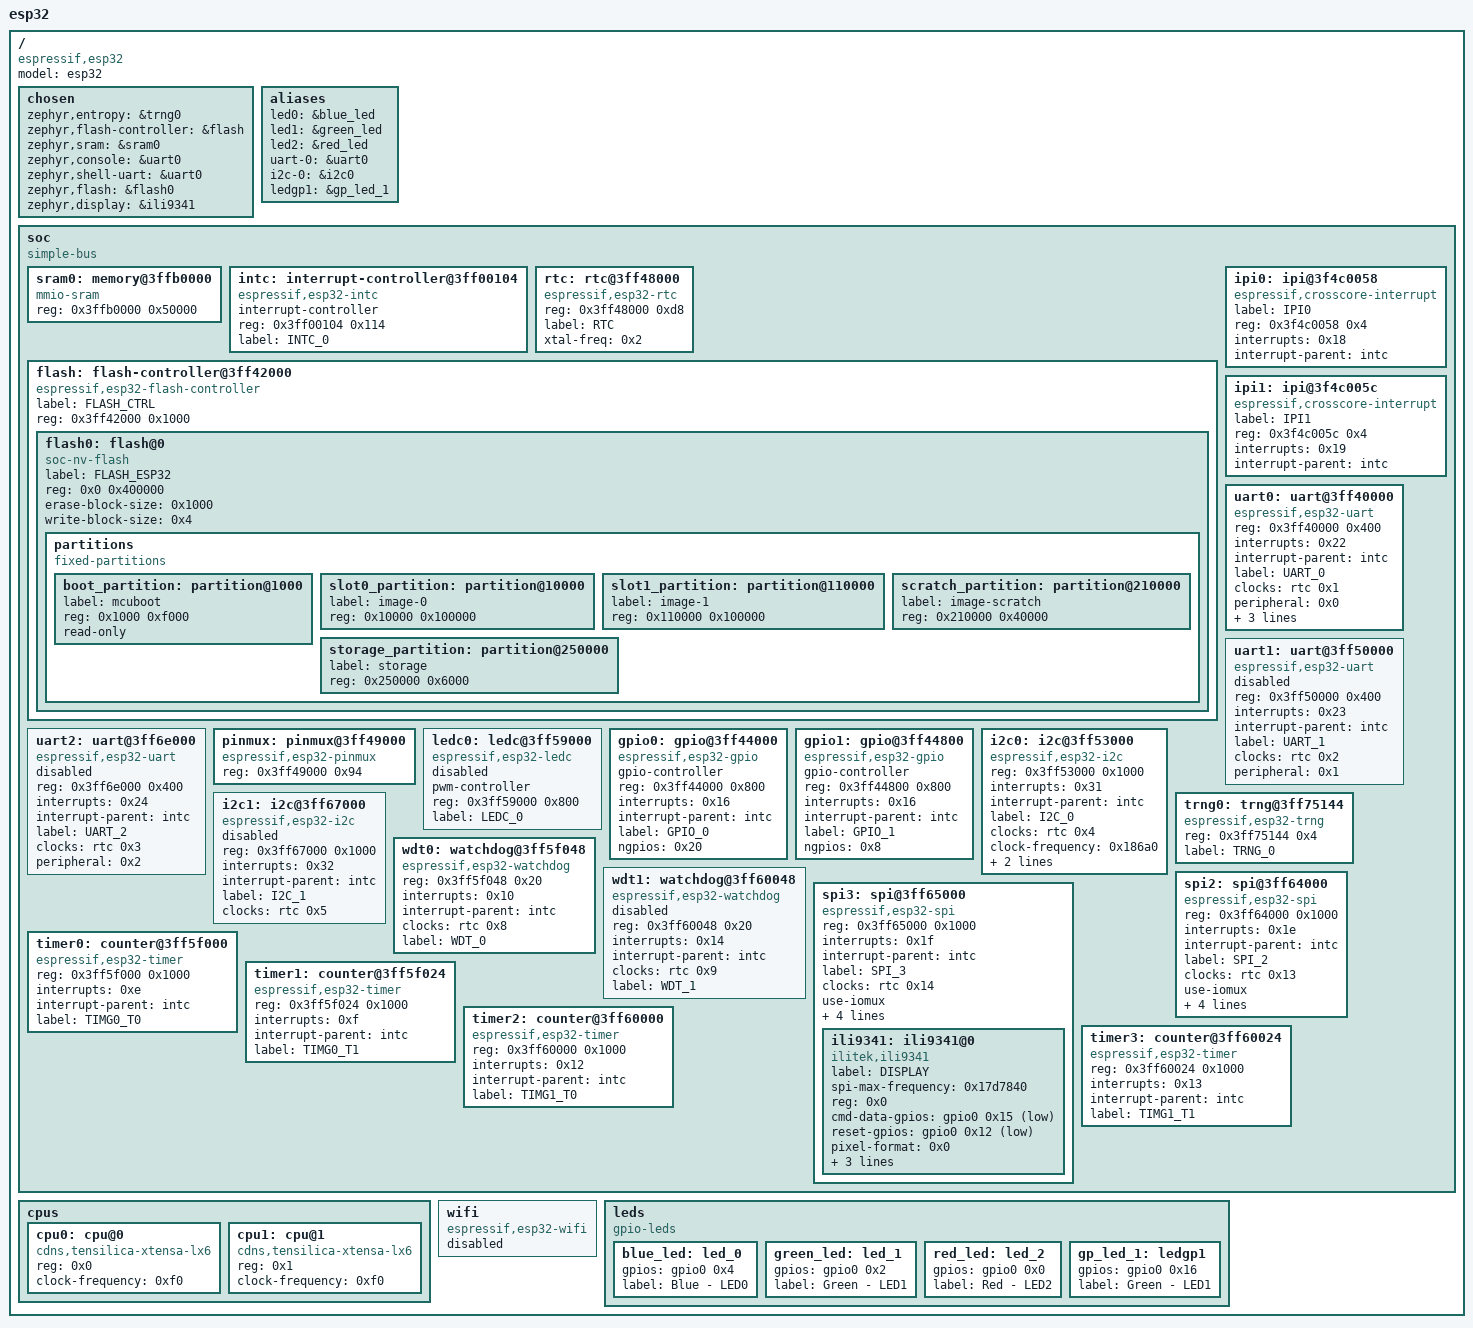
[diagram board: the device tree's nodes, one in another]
/dts-v1/;

/ {
	#address-cells = < 0x1 >;
	#size-cells = < 0x1 >;
	model = "esp32";
	compatible = "espressif,esp32";
	chosen {
		zephyr,entropy = &trng0;
		zephyr,flash-controller = &flash;
		zephyr,sram = &sram0;
		zephyr,console = &uart0;
		zephyr,shell-uart = &uart0;
		zephyr,flash = &flash0;
		zephyr,display = &ili9341;
	};
	aliases {
		led0 = &blue_led;
		led1 = &green_led;
		led2 = &red_led;
		uart-0 = &uart0;
		i2c-0 = &i2c0;
		ledgp1 = &gp_led_1;
	};
	soc {
		#address-cells = < 0x1 >;
		#size-cells = < 0x1 >;
		compatible = "simple-bus";
		ranges;
		sram0: memory@3ffb0000 {
			compatible = "mmio-sram";
			reg = < 0x3ffb0000 0x50000 >;
		};
		intc: interrupt-controller@3ff00104 {
			#interrupt-cells = < 0x1 >;
			compatible = "espressif,esp32-intc";
			interrupt-controller;
			reg = < 0x3ff00104 0x114 >;
			label = "INTC_0";
			status = "okay";
			phandle = < 0x1 >;
		};
		rtc: rtc@3ff48000 {
			compatible = "espressif,esp32-rtc";
			reg = < 0x3ff48000 0xd8 >;
			label = "RTC";
			xtal-freq = < 0x2 >;
			#clock-cells = < 0x1 >;
			status = "ok";
			phandle = < 0x2 >;
		};
		flash: flash-controller@3ff42000 {
			compatible = "espressif,esp32-flash-controller";
			label = "FLASH_CTRL";
			reg = < 0x3ff42000 0x1000 >;
			#address-cells = < 0x1 >;
			#size-cells = < 0x1 >;
			flash0: flash@0 {
				compatible = "soc-nv-flash";
				label = "FLASH_ESP32";
				reg = < 0x0 0x400000 >;
				erase-block-size = < 0x1000 >;
				write-block-size = < 0x4 >;
				status = "okay";
				partitions {
					compatible = "fixed-partitions";
					#address-cells = < 0x1 >;
					#size-cells = < 0x1 >;
					boot_partition: partition@1000 {
						label = "mcuboot";
						reg = < 0x1000 0xf000 >;
						read-only;
					};
					slot0_partition: partition@10000 {
						label = "image-0";
						reg = < 0x10000 0x100000 >;
					};
					slot1_partition: partition@110000 {
						label = "image-1";
						reg = < 0x110000 0x100000 >;
					};
					scratch_partition: partition@210000 {
						label = "image-scratch";
						reg = < 0x210000 0x40000 >;
					};
					storage_partition: partition@250000 {
						label = "storage";
						reg = < 0x250000 0x6000 >;
					};
				};
			};
		};
		ipi0: ipi@3f4c0058 {
			compatible = "espressif,crosscore-interrupt";
			label = "IPI0";
			reg = < 0x3f4c0058 0x4 >;
			interrupts = < 0x18 >;
			interrupt-parent = < &intc >;
		};
		ipi1: ipi@3f4c005c {
			compatible = "espressif,crosscore-interrupt";
			label = "IPI1";
			reg = < 0x3f4c005c 0x4 >;
			interrupts = < 0x19 >;
			interrupt-parent = < &intc >;
		};
		uart0: uart@3ff40000 {
			compatible = "espressif,esp32-uart";
			reg = < 0x3ff40000 0x400 >;
			interrupts = < 0x22 >;
			interrupt-parent = < &intc >;
			label = "UART_0";
			clocks = < &rtc 0x1 >;
			status = "okay";
			peripheral = < 0x0 >;
			current-speed = < 0x1c200 >;
			tx-pin = < 0x1 >;
			rx-pin = < 0x3 >;
		};
		uart1: uart@3ff50000 {
			compatible = "espressif,esp32-uart";
			reg = < 0x3ff50000 0x400 >;
			interrupts = < 0x23 >;
			interrupt-parent = < &intc >;
			label = "UART_1";
			clocks = < &rtc 0x2 >;
			status = "disabled";
			peripheral = < 0x1 >;
		};
		uart2: uart@3ff6e000 {
			compatible = "espressif,esp32-uart";
			reg = < 0x3ff6e000 0x400 >;
			interrupts = < 0x24 >;
			interrupt-parent = < &intc >;
			label = "UART_2";
			clocks = < &rtc 0x3 >;
			status = "disabled";
			peripheral = < 0x2 >;
		};
		pinmux: pinmux@3ff49000 {
			compatible = "espressif,esp32-pinmux";
			reg = < 0x3ff49000 0x94 >;
		};
		ledc0: ledc@3ff59000 {
			compatible = "espressif,esp32-ledc";
			pwm-controller;
			#pwm-cells = < 0x3 >;
			reg = < 0x3ff59000 0x800 >;
			label = "LEDC_0";
			status = "disabled";
		};
		gpio0: gpio@3ff44000 {
			compatible = "espressif,esp32-gpio";
			gpio-controller;
			#gpio-cells = < 0x2 >;
			reg = < 0x3ff44000 0x800 >;
			interrupts = < 0x16 >;
			interrupt-parent = < &intc >;
			label = "GPIO_0";
			ngpios = < 0x20 >;
			status = "okay";
			phandle = < 0x3 >;
		};
		gpio1: gpio@3ff44800 {
			compatible = "espressif,esp32-gpio";
			gpio-controller;
			#gpio-cells = < 0x2 >;
			reg = < 0x3ff44800 0x800 >;
			interrupts = < 0x16 >;
			interrupt-parent = < &intc >;
			label = "GPIO_1";
			ngpios = < 0x8 >;
			status = "okay";
		};
		i2c0: i2c@3ff53000 {
			compatible = "espressif,esp32-i2c";
			#address-cells = < 0x1 >;
			#size-cells = < 0x0 >;
			reg = < 0x3ff53000 0x1000 >;
			interrupts = < 0x31 >;
			interrupt-parent = < &intc >;
			label = "I2C_0";
			clocks = < &rtc 0x4 >;
			status = "okay";
			clock-frequency = < 0x186a0 >;
			sda-pin = < 0x15 >;
			scl-pin = < 0x16 >;
		};
		i2c1: i2c@3ff67000 {
			compatible = "espressif,esp32-i2c";
			#address-cells = < 0x1 >;
			#size-cells = < 0x0 >;
			reg = < 0x3ff67000 0x1000 >;
			interrupts = < 0x32 >;
			interrupt-parent = < &intc >;
			label = "I2C_1";
			clocks = < &rtc 0x5 >;
			status = "disabled";
		};
		trng0: trng@3ff75144 {
			compatible = "espressif,esp32-trng";
			reg = < 0x3ff75144 0x4 >;
			label = "TRNG_0";
			status = "okay";
		};
		wdt0: watchdog@3ff5f048 {
			compatible = "espressif,esp32-watchdog";
			reg = < 0x3ff5f048 0x20 >;
			interrupts = < 0x10 >;
			interrupt-parent = < &intc >;
			clocks = < &rtc 0x8 >;
			label = "WDT_0";
			status = "okay";
		};
		wdt1: watchdog@3ff60048 {
			compatible = "espressif,esp32-watchdog";
			reg = < 0x3ff60048 0x20 >;
			interrupts = < 0x14 >;
			interrupt-parent = < &intc >;
			clocks = < &rtc 0x9 >;
			label = "WDT_1";
			status = "disabled";
		};
		spi2: spi@3ff64000 {
			compatible = "espressif,esp32-spi";
			reg = < 0x3ff64000 0x1000 >;
			interrupts = < 0x1e >;
			interrupt-parent = < &intc >;
			label = "SPI_2";
			clocks = < &rtc 0x13 >;
			status = "okay";
			use-iomux;
			#address-cells = < 0x1 >;
			#size-cells = < 0x0 >;
			miso-pin = < 0xc >;
			mosi-pin = < 0xd >;
			sclk-pin = < 0xe >;
			csel-pin = < 0xf >;
		};
		spi3: spi@3ff65000 {
			compatible = "espressif,esp32-spi";
			reg = < 0x3ff65000 0x1000 >;
			interrupts = < 0x1f >;
			interrupt-parent = < &intc >;
			label = "SPI_3";
			clocks = < &rtc 0x14 >;
			status = "okay";
			use-iomux;
			#address-cells = < 0x1 >;
			#size-cells = < 0x0 >;
			miso-pin = < 0x19 >;
			mosi-pin = < 0x17 >;
			sclk-pin = < 0x13 >;
			csel-pin = < 0x16 >;
			ili9341: ili9341@0 {
				compatible = "ilitek,ili9341";
				label = "DISPLAY";
				spi-max-frequency = < 0x17d7840 >;
				reg = < 0x0 >;
				cmd-data-gpios = < &gpio0 0x15 0x1 >;
				reset-gpios = < &gpio0 0x12 0x1 >;
				pixel-format = < 0x0 >;
				rotation = < 0x0 >;
				width = < 0xf0 >;
				height = < 0x140 >;
			};
		};
		timer0: counter@3ff5f000 {
			compatible = "espressif,esp32-timer";
			reg = < 0x3ff5f000 0x1000 >;
			interrupts = < 0xe >;
			interrupt-parent = < &intc >;
			label = "TIMG0_T0";
			status = "okay";
		};
		timer1: counter@3ff5f024 {
			compatible = "espressif,esp32-timer";
			reg = < 0x3ff5f024 0x1000 >;
			interrupts = < 0xf >;
			interrupt-parent = < &intc >;
			label = "TIMG0_T1";
			status = "okay";
		};
		timer2: counter@3ff60000 {
			compatible = "espressif,esp32-timer";
			reg = < 0x3ff60000 0x1000 >;
			interrupts = < 0x12 >;
			interrupt-parent = < &intc >;
			label = "TIMG1_T0";
			status = "okay";
		};
		timer3: counter@3ff60024 {
			compatible = "espressif,esp32-timer";
			reg = < 0x3ff60024 0x1000 >;
			interrupts = < 0x13 >;
			interrupt-parent = < &intc >;
			label = "TIMG1_T1";
			status = "okay";
		};
	};
	cpus {
		#address-cells = < 0x1 >;
		#size-cells = < 0x0 >;
		cpu0: cpu@0 {
			device_type = "cpu";
			compatible = "cdns,tensilica-xtensa-lx6";
			reg = < 0x0 >;
			clock-frequency = < 0xf0 >;
		};
		cpu1: cpu@1 {
			device_type = "cpu";
			compatible = "cdns,tensilica-xtensa-lx6";
			reg = < 0x1 >;
			clock-frequency = < 0xf0 >;
		};
	};
	wifi: wifi {
		compatible = "espressif,esp32-wifi";
		status = "disabled";
	};
	leds {
		compatible = "gpio-leds";
		blue_led: led_0 {
			gpios = < &gpio0 0x4 0x0 >;
			label = "Blue - LED0";
		};
		green_led: led_1 {
			gpios = < &gpio0 0x2 0x0 >;
			label = "Green - LED1";
		};
		red_led: led_2 {
			gpios = < &gpio0 0x0 0x0 >;
			label = "Red - LED2";
		};
		gp_led_1: ledgp1 {
			gpios = < &gpio0 0x16 0x0 >;
			label = "Green - LED1";
		};
	};
};
